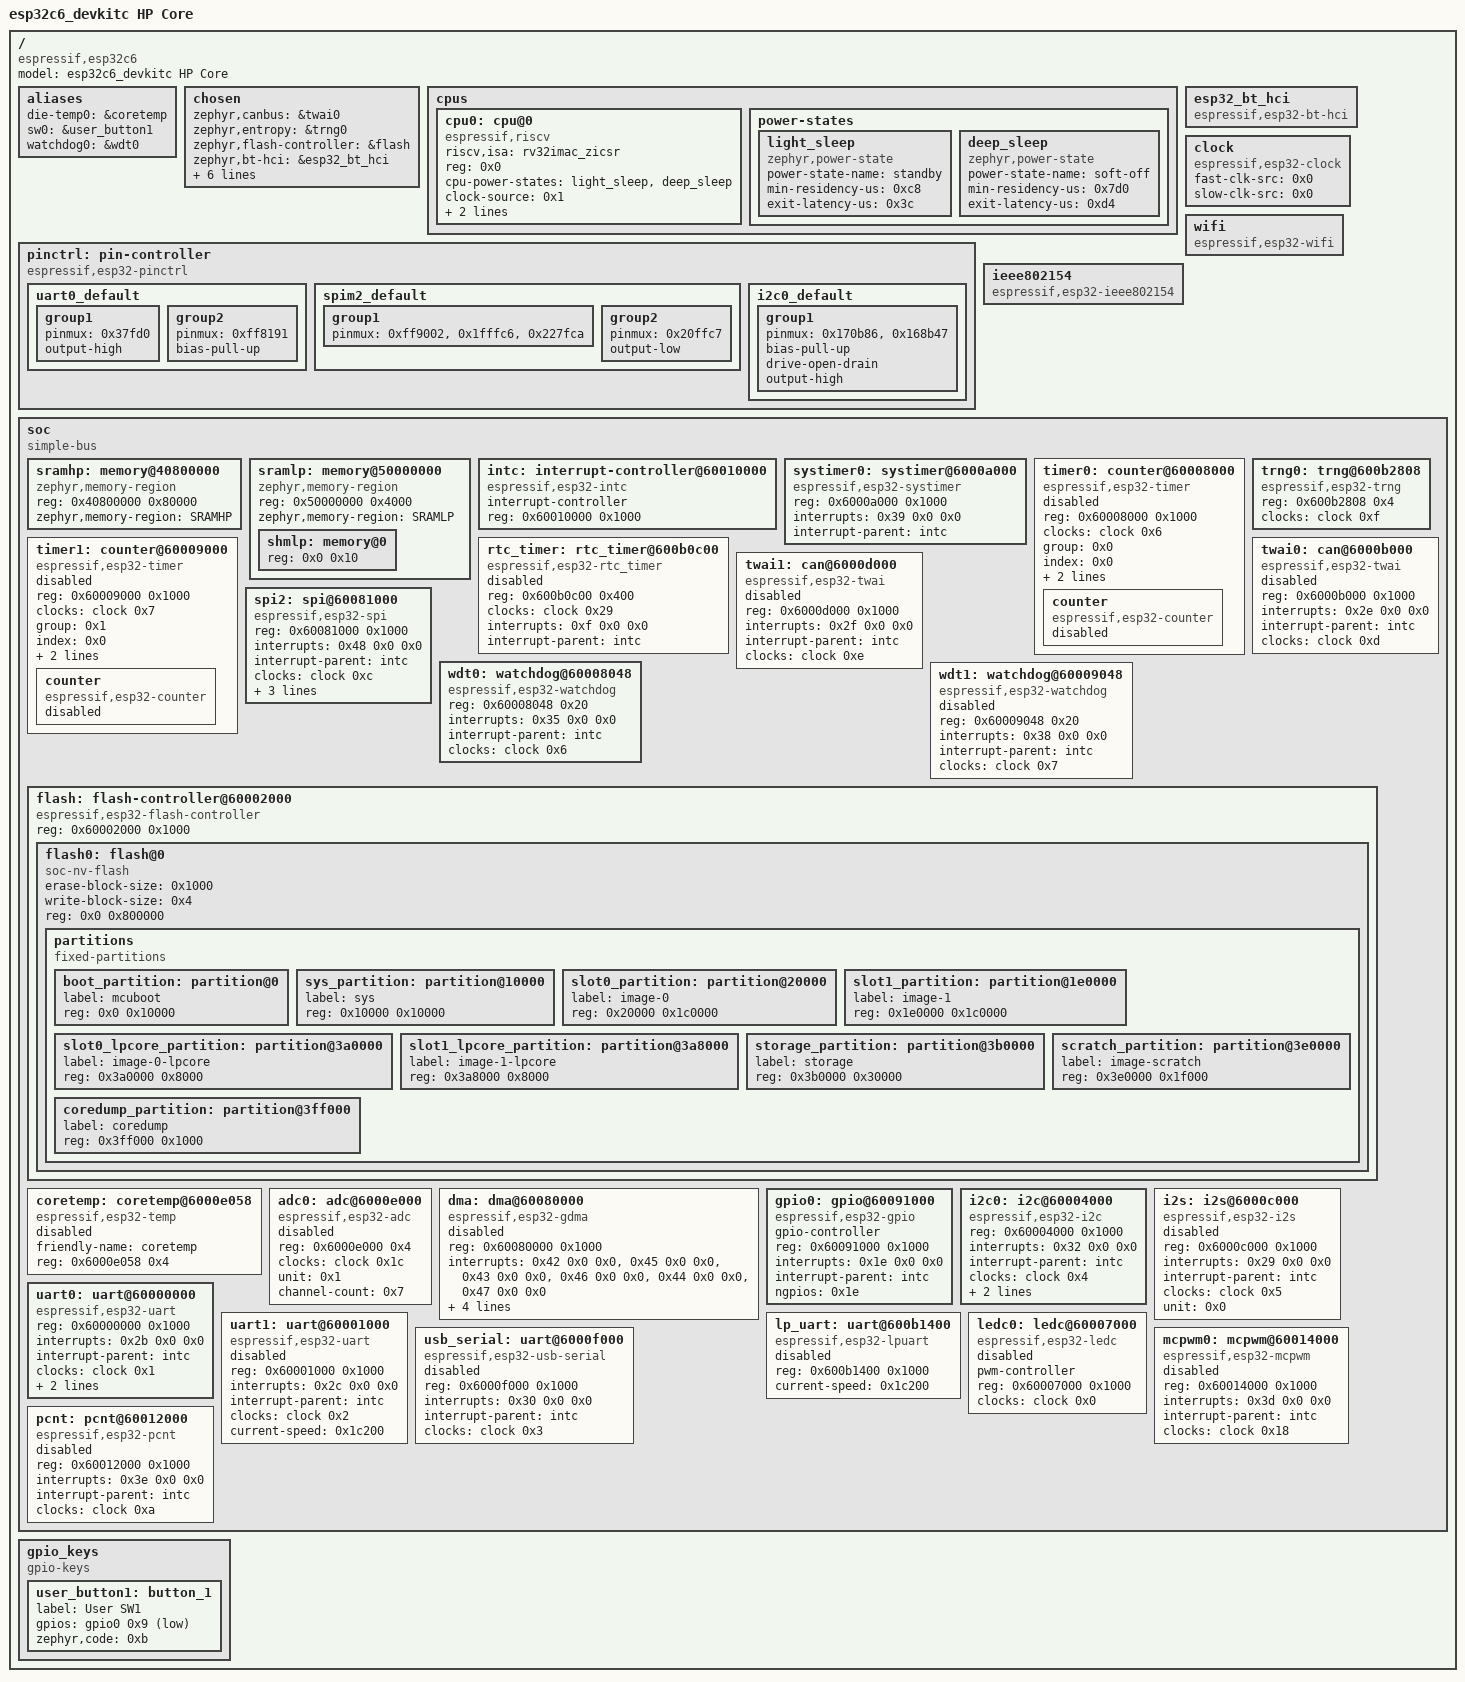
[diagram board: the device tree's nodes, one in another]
/dts-v1/;

/* node '/' defined in zephyr/dts/riscv/espressif/esp32c6/esp32c6_common.dtsi:15 */
/ {
	#address-cells = < 0x1 >;          /* in zephyr/dts/riscv/espressif/esp32c6/esp32c6_common.dtsi:16 */
	#size-cells = < 0x1 >;             /* in zephyr/dts/riscv/espressif/esp32c6/esp32c6_common.dtsi:17 */
	model = "esp32c6_devkitc HP Core"; /* in zephyr/boards/espressif/esp32c6_devkitc/esp32c6_devkitc_hpcore.dts:15 */
	compatible = "espressif,esp32c6";  /* in zephyr/boards/espressif/esp32c6_devkitc/esp32c6_devkitc_hpcore.dts:16 */

	/* node '/aliases' defined in zephyr/dts/riscv/espressif/esp32c6/esp32c6_common.dtsi:19 */
	aliases {
		die-temp0 = &coretemp; /* in zephyr/dts/riscv/espressif/esp32c6/esp32c6_common.dtsi:20 */
		sw0 = &user_button1;   /* in zephyr/boards/espressif/esp32c6_devkitc/esp32c6_devkitc_hpcore.dts:28 */
		watchdog0 = &wdt0;     /* in zephyr/boards/espressif/esp32c6_devkitc/esp32c6_devkitc_hpcore.dts:29 */
	};

	/* node '/chosen' defined in zephyr/dts/riscv/espressif/esp32c6/esp32c6_common.dtsi:23 */
	chosen {
		zephyr,canbus = &twai0;                   /* in zephyr/dts/riscv/espressif/esp32c6/esp32c6_common.dtsi:24 */
		zephyr,entropy = &trng0;                  /* in zephyr/dts/riscv/espressif/esp32c6/esp32c6_common.dtsi:25 */
		zephyr,flash-controller = &flash;         /* in zephyr/dts/riscv/espressif/esp32c6/esp32c6_common.dtsi:26 */
		zephyr,bt-hci = &esp32_bt_hci;            /* in zephyr/dts/riscv/espressif/esp32c6/esp32c6_common.dtsi:27 */
		zephyr,sram = &sramhp;                    /* in zephyr/boards/espressif/esp32c6_devkitc/esp32c6_devkitc_hpcore.dts:19 */
		zephyr,console = &uart0;                  /* in zephyr/boards/espressif/esp32c6_devkitc/esp32c6_devkitc_hpcore.dts:20 */
		zephyr,shell-uart = &uart0;               /* in zephyr/boards/espressif/esp32c6_devkitc/esp32c6_devkitc_hpcore.dts:21 */
		zephyr,flash = &flash0;                   /* in zephyr/boards/espressif/esp32c6_devkitc/esp32c6_devkitc_hpcore.dts:22 */
		zephyr,code-partition = &slot0_partition; /* in zephyr/boards/espressif/esp32c6_devkitc/esp32c6_devkitc_hpcore.dts:23 */
		zephyr,ieee802154 = &ieee802154;          /* in zephyr/boards/espressif/esp32c6_devkitc/esp32c6_devkitc_hpcore.dts:24 */
	};

	/* node '/cpus' defined in zephyr/dts/riscv/espressif/esp32c6/esp32c6_common.dtsi:30 */
	cpus {
		#address-cells = < 0x1 >; /* in zephyr/dts/riscv/espressif/esp32c6/esp32c6_common.dtsi:31 */
		#size-cells = < 0x0 >;    /* in zephyr/dts/riscv/espressif/esp32c6/esp32c6_common.dtsi:32 */

		/* node '/cpus/cpu@0' defined in zephyr/dts/riscv/espressif/esp32c6/esp32c6_common.dtsi:34 */
		cpu0: cpu@0 {
			device_type = "cpu";                             /* in zephyr/dts/riscv/espressif/esp32c6/esp32c6_common.dtsi:35 */
			compatible = "espressif,riscv";                  /* in zephyr/dts/riscv/espressif/esp32c6/esp32c6_common.dtsi:36 */
			riscv,isa = "rv32imac_zicsr";                    /* in zephyr/dts/riscv/espressif/esp32c6/esp32c6_common.dtsi:37 */
			reg = < 0x0 >;                                   /* in zephyr/dts/riscv/espressif/esp32c6/esp32c6_common.dtsi:38 */
			cpu-power-states = < &light_sleep &deep_sleep >; /* in zephyr/dts/riscv/espressif/esp32c6/esp32c6_common.dtsi:39 */
			clock-source = < 0x1 >;                          /* in zephyr/dts/riscv/espressif/esp32c6/esp32c6_common.dtsi:40 */
			clock-frequency = < 0x9896800 >;                 /* in zephyr/dts/riscv/espressif/esp32c6/esp32c6_common.dtsi:41 */
			xtal-freq = < 0x2625a00 >;                       /* in zephyr/dts/riscv/espressif/esp32c6/esp32c6_common.dtsi:42 */
		};

		/* node '/cpus/power-states' defined in zephyr/dts/riscv/espressif/esp32c6/esp32c6_common.dtsi:45 */
		power-states {

			/* node '/cpus/power-states/light_sleep' defined in zephyr/dts/riscv/espressif/esp32c6/esp32c6_common.dtsi:46 */
			light_sleep: light_sleep {
				compatible = "zephyr,power-state"; /* in zephyr/dts/riscv/espressif/esp32c6/esp32c6_common.dtsi:47 */
				power-state-name = "standby";      /* in zephyr/dts/riscv/espressif/esp32c6/esp32c6_common.dtsi:48 */
				min-residency-us = < 0xc8 >;       /* in zephyr/dts/riscv/espressif/esp32c6/esp32c6_common.dtsi:49 */
				exit-latency-us = < 0x3c >;        /* in zephyr/dts/riscv/espressif/esp32c6/esp32c6_common.dtsi:50 */
				phandle = < 0x1 >;                 /* in zephyr/dts/riscv/espressif/esp32c6/esp32c6_common.dtsi:39 */
			};

			/* node '/cpus/power-states/deep_sleep' defined in zephyr/dts/riscv/espressif/esp32c6/esp32c6_common.dtsi:53 */
			deep_sleep: deep_sleep {
				compatible = "zephyr,power-state"; /* in zephyr/dts/riscv/espressif/esp32c6/esp32c6_common.dtsi:54 */
				power-state-name = "soft-off";     /* in zephyr/dts/riscv/espressif/esp32c6/esp32c6_common.dtsi:55 */
				min-residency-us = < 0x7d0 >;      /* in zephyr/dts/riscv/espressif/esp32c6/esp32c6_common.dtsi:56 */
				exit-latency-us = < 0xd4 >;        /* in zephyr/dts/riscv/espressif/esp32c6/esp32c6_common.dtsi:57 */
				phandle = < 0x2 >;                 /* in zephyr/dts/riscv/espressif/esp32c6/esp32c6_common.dtsi:39 */
			};
		};
	};

	/* node '/pin-controller' defined in zephyr/dts/riscv/espressif/esp32c6/esp32c6_common.dtsi:62 */
	pinctrl: pin-controller {
		compatible = "espressif,esp32-pinctrl"; /* in zephyr/dts/riscv/espressif/esp32c6/esp32c6_common.dtsi:63 */
		status = "okay";                        /* in zephyr/dts/riscv/espressif/esp32c6/esp32c6_common.dtsi:64 */

		/* node '/pin-controller/uart0_default' defined in zephyr/boards/espressif/esp32c6_devkitc/esp32c6_devkitc_hpcore-pinctrl.dtsi:13 */
		uart0_default: uart0_default {
			phandle = < 0x7 >; /* in zephyr/boards/espressif/esp32c6_devkitc/esp32c6_devkitc_hpcore.dts:45 */

			/* node '/pin-controller/uart0_default/group1' defined in zephyr/boards/espressif/esp32c6_devkitc/esp32c6_devkitc_hpcore-pinctrl.dtsi:14 */
			group1 {
				pinmux = < 0x37fd0 >; /* in zephyr/boards/espressif/esp32c6_devkitc/esp32c6_devkitc_hpcore-pinctrl.dtsi:15 */
				output-high;          /* in zephyr/boards/espressif/esp32c6_devkitc/esp32c6_devkitc_hpcore-pinctrl.dtsi:16 */
			};

			/* node '/pin-controller/uart0_default/group2' defined in zephyr/boards/espressif/esp32c6_devkitc/esp32c6_devkitc_hpcore-pinctrl.dtsi:18 */
			group2 {
				pinmux = < 0xff8191 >; /* in zephyr/boards/espressif/esp32c6_devkitc/esp32c6_devkitc_hpcore-pinctrl.dtsi:19 */
				bias-pull-up;          /* in zephyr/boards/espressif/esp32c6_devkitc/esp32c6_devkitc_hpcore-pinctrl.dtsi:20 */
			};
		};

		/* node '/pin-controller/spim2_default' defined in zephyr/boards/espressif/esp32c6_devkitc/esp32c6_devkitc_hpcore-pinctrl.dtsi:24 */
		spim2_default: spim2_default {
			phandle = < 0x5 >; /* in zephyr/boards/espressif/esp32c6_devkitc/esp32c6_devkitc_hpcore.dts:64 */

			/* node '/pin-controller/spim2_default/group1' defined in zephyr/boards/espressif/esp32c6_devkitc/esp32c6_devkitc_hpcore-pinctrl.dtsi:25 */
			group1 {
				pinmux = < 0xff9002 >,
				         < 0x1fffc6 >,
				         < 0x227fca >; /* in zephyr/boards/espressif/esp32c6_devkitc/esp32c6_devkitc_hpcore-pinctrl.dtsi:26 */
			};

			/* node '/pin-controller/spim2_default/group2' defined in zephyr/boards/espressif/esp32c6_devkitc/esp32c6_devkitc_hpcore-pinctrl.dtsi:30 */
			group2 {
				pinmux = < 0x20ffc7 >; /* in zephyr/boards/espressif/esp32c6_devkitc/esp32c6_devkitc_hpcore-pinctrl.dtsi:31 */
				output-low;            /* in zephyr/boards/espressif/esp32c6_devkitc/esp32c6_devkitc_hpcore-pinctrl.dtsi:32 */
			};
		};

		/* node '/pin-controller/i2c0_default' defined in zephyr/boards/espressif/esp32c6_devkitc/esp32c6_devkitc_hpcore-pinctrl.dtsi:36 */
		i2c0_default: i2c0_default {
			phandle = < 0x6 >; /* in zephyr/boards/espressif/esp32c6_devkitc/esp32c6_devkitc_hpcore.dts:56 */

			/* node '/pin-controller/i2c0_default/group1' defined in zephyr/boards/espressif/esp32c6_devkitc/esp32c6_devkitc_hpcore-pinctrl.dtsi:37 */
			group1 {
				pinmux = < 0x170b86 >,
				         < 0x168b47 >; /* in zephyr/boards/espressif/esp32c6_devkitc/esp32c6_devkitc_hpcore-pinctrl.dtsi:38 */
				bias-pull-up;          /* in zephyr/boards/espressif/esp32c6_devkitc/esp32c6_devkitc_hpcore-pinctrl.dtsi:40 */
				drive-open-drain;      /* in zephyr/boards/espressif/esp32c6_devkitc/esp32c6_devkitc_hpcore-pinctrl.dtsi:41 */
				output-high;           /* in zephyr/boards/espressif/esp32c6_devkitc/esp32c6_devkitc_hpcore-pinctrl.dtsi:42 */
			};
		};
	};

	/* node '/esp32_bt_hci' defined in zephyr/dts/riscv/espressif/esp32c6/esp32c6_common.dtsi:67 */
	esp32_bt_hci: esp32_bt_hci {
		compatible = "espressif,esp32-bt-hci"; /* in zephyr/dts/riscv/espressif/esp32c6/esp32c6_common.dtsi:68 */
		status = "okay";                       /* in zephyr/boards/espressif/esp32c6_devkitc/esp32c6_devkitc_hpcore.dts:85 */
	};

	/* node '/clock' defined in zephyr/dts/riscv/espressif/esp32c6/esp32c6_common.dtsi:72 */
	clock: clock {
		compatible = "espressif,esp32-clock"; /* in zephyr/dts/riscv/espressif/esp32c6/esp32c6_common.dtsi:73 */
		fast-clk-src = < 0x0 >;               /* in zephyr/dts/riscv/espressif/esp32c6/esp32c6_common.dtsi:74 */
		slow-clk-src = < 0x0 >;               /* in zephyr/dts/riscv/espressif/esp32c6/esp32c6_common.dtsi:75 */
		#clock-cells = < 0x1 >;               /* in zephyr/dts/riscv/espressif/esp32c6/esp32c6_common.dtsi:76 */
		status = "okay";                      /* in zephyr/dts/riscv/espressif/esp32c6/esp32c6_common.dtsi:77 */
		phandle = < 0x4 >;                    /* in zephyr/dts/riscv/espressif/esp32c6/esp32c6_common.dtsi:134 */
	};

	/* node '/wifi' defined in zephyr/dts/riscv/espressif/esp32c6/esp32c6_common.dtsi:80 */
	wifi: wifi {
		compatible = "espressif,esp32-wifi"; /* in zephyr/dts/riscv/espressif/esp32c6/esp32c6_common.dtsi:81 */
		status = "okay";                     /* in zephyr/boards/espressif/esp32c6_devkitc/esp32c6_devkitc_hpcore.dts:77 */
	};

	/* node '/ieee802154' defined in zephyr/dts/riscv/espressif/esp32c6/esp32c6_common.dtsi:85 */
	ieee802154: ieee802154 {
		compatible = "espressif,esp32-ieee802154"; /* in zephyr/dts/riscv/espressif/esp32c6/esp32c6_common.dtsi:86 */
		status = "okay";                           /* in zephyr/boards/espressif/esp32c6_devkitc/esp32c6_devkitc_hpcore.dts:81 */
	};

	/* node '/soc' defined in zephyr/dts/riscv/espressif/esp32c6/esp32c6_common.dtsi:90 */
	soc {
		#address-cells = < 0x1 >;  /* in zephyr/dts/riscv/espressif/esp32c6/esp32c6_common.dtsi:91 */
		#size-cells = < 0x1 >;     /* in zephyr/dts/riscv/espressif/esp32c6/esp32c6_common.dtsi:92 */
		compatible = "simple-bus"; /* in zephyr/dts/riscv/espressif/esp32c6/esp32c6_common.dtsi:93 */
		ranges;                    /* in zephyr/dts/riscv/espressif/esp32c6/esp32c6_common.dtsi:94 */

		/* node '/soc/memory@40800000' defined in zephyr/dts/riscv/espressif/esp32c6/esp32c6_common.dtsi:96 */
		sramhp: memory@40800000 {
			compatible = "zephyr,memory-region",
			             "mmio-sram";            /* in zephyr/dts/riscv/espressif/esp32c6/esp32c6_common.dtsi:97 */
			reg = < 0x40800000 0x80000 >;        /* in zephyr/dts/riscv/espressif/esp32c6/esp32c6_common.dtsi:98 */
			zephyr,memory-region = "SRAMHP";     /* in zephyr/dts/riscv/espressif/esp32c6/esp32c6_common.dtsi:99 */
		};

		/* node '/soc/memory@50000000' defined in zephyr/dts/riscv/espressif/esp32c6/esp32c6_common.dtsi:102 */
		sramlp: memory@50000000 {
			#address-cells = < 0x1 >;            /* in zephyr/dts/riscv/espressif/esp32c6/esp32c6_common.dtsi:103 */
			#size-cells = < 0x1 >;               /* in zephyr/dts/riscv/espressif/esp32c6/esp32c6_common.dtsi:104 */
			compatible = "zephyr,memory-region",
			             "mmio-sram";            /* in zephyr/dts/riscv/espressif/esp32c6/esp32c6_common.dtsi:105 */
			reg = < 0x50000000 0x4000 >;         /* in zephyr/dts/riscv/espressif/esp32c6/esp32c6_common.dtsi:106 */
			zephyr,memory-region = "SRAMLP ";    /* in zephyr/dts/riscv/espressif/esp32c6/esp32c6_common.dtsi:107 */

			/* node '/soc/memory@50000000/memory@0' defined in zephyr/dts/riscv/espressif/esp32c6/esp32c6_common.dtsi:109 */
			shmlp: memory@0 {
				reg = < 0x0 0x10 >; /* in zephyr/dts/riscv/espressif/esp32c6/esp32c6_common.dtsi:110 */
			};
		};

		/* node '/soc/interrupt-controller@60010000' defined in zephyr/dts/riscv/espressif/esp32c6/esp32c6_common.dtsi:114 */
		intc: interrupt-controller@60010000 {
			compatible = "espressif,esp32-intc"; /* in zephyr/dts/riscv/espressif/esp32c6/esp32c6_common.dtsi:115 */
			#address-cells = < 0x0 >;            /* in zephyr/dts/riscv/espressif/esp32c6/esp32c6_common.dtsi:116 */
			#interrupt-cells = < 0x3 >;          /* in zephyr/dts/riscv/espressif/esp32c6/esp32c6_common.dtsi:117 */
			interrupt-controller;                /* in zephyr/dts/riscv/espressif/esp32c6/esp32c6_common.dtsi:118 */
			reg = < 0x60010000 0x1000 >;         /* in zephyr/dts/riscv/espressif/esp32c6/esp32c6_common.dtsi:119 */
			status = "okay";                     /* in zephyr/dts/riscv/espressif/esp32c6/esp32c6_common.dtsi:120 */
			phandle = < 0x3 >;                   /* in zephyr/dts/riscv/espressif/esp32c6/esp32c6_common.dtsi:127 */
		};

		/* node '/soc/systimer@6000a000' defined in zephyr/dts/riscv/espressif/esp32c6/esp32c6_common.dtsi:123 */
		systimer0: systimer@6000a000 {
			compatible = "espressif,esp32-systimer"; /* in zephyr/dts/riscv/espressif/esp32c6/esp32c6_common.dtsi:124 */
			reg = < 0x6000a000 0x1000 >;             /* in zephyr/dts/riscv/espressif/esp32c6/esp32c6_common.dtsi:125 */
			interrupts = < 0x39 0x0 0x0 >;           /* in zephyr/dts/riscv/espressif/esp32c6/esp32c6_common.dtsi:126 */
			interrupt-parent = < &intc >;            /* in zephyr/dts/riscv/espressif/esp32c6/esp32c6_common.dtsi:127 */
			status = "okay";                         /* in zephyr/dts/riscv/espressif/esp32c6/esp32c6_common.dtsi:128 */
		};

		/* node '/soc/counter@60008000' defined in zephyr/dts/riscv/espressif/esp32c6/esp32c6_common.dtsi:131 */
		timer0: counter@60008000 {
			compatible = "espressif,esp32-timer"; /* in zephyr/dts/riscv/espressif/esp32c6/esp32c6_common.dtsi:132 */
			reg = < 0x60008000 0x1000 >;          /* in zephyr/dts/riscv/espressif/esp32c6/esp32c6_common.dtsi:133 */
			clocks = < &clock 0x6 >;              /* in zephyr/dts/riscv/espressif/esp32c6/esp32c6_common.dtsi:134 */
			group = < 0x0 >;                      /* in zephyr/dts/riscv/espressif/esp32c6/esp32c6_common.dtsi:135 */
			index = < 0x0 >;                      /* in zephyr/dts/riscv/espressif/esp32c6/esp32c6_common.dtsi:136 */
			interrupts = < 0x33 0x0 0x0 >;        /* in zephyr/dts/riscv/espressif/esp32c6/esp32c6_common.dtsi:137 */
			interrupt-parent = < &intc >;         /* in zephyr/dts/riscv/espressif/esp32c6/esp32c6_common.dtsi:138 */
			status = "disabled";                  /* in zephyr/dts/riscv/espressif/esp32c6/esp32c6_common.dtsi:139 */

			/* node '/soc/counter@60008000/counter' defined in zephyr/dts/riscv/espressif/esp32c6/esp32c6_common.dtsi:141 */
			counter {
				compatible = "espressif,esp32-counter"; /* in zephyr/dts/riscv/espressif/esp32c6/esp32c6_common.dtsi:142 */
				status = "disabled";                    /* in zephyr/dts/riscv/espressif/esp32c6/esp32c6_common.dtsi:143 */
			};
		};

		/* node '/soc/counter@60009000' defined in zephyr/dts/riscv/espressif/esp32c6/esp32c6_common.dtsi:147 */
		timer1: counter@60009000 {
			compatible = "espressif,esp32-timer"; /* in zephyr/dts/riscv/espressif/esp32c6/esp32c6_common.dtsi:148 */
			reg = < 0x60009000 0x1000 >;          /* in zephyr/dts/riscv/espressif/esp32c6/esp32c6_common.dtsi:149 */
			clocks = < &clock 0x7 >;              /* in zephyr/dts/riscv/espressif/esp32c6/esp32c6_common.dtsi:150 */
			group = < 0x1 >;                      /* in zephyr/dts/riscv/espressif/esp32c6/esp32c6_common.dtsi:151 */
			index = < 0x0 >;                      /* in zephyr/dts/riscv/espressif/esp32c6/esp32c6_common.dtsi:152 */
			interrupts = < 0x36 0x0 0x0 >;        /* in zephyr/dts/riscv/espressif/esp32c6/esp32c6_common.dtsi:153 */
			interrupt-parent = < &intc >;         /* in zephyr/dts/riscv/espressif/esp32c6/esp32c6_common.dtsi:154 */
			status = "disabled";                  /* in zephyr/dts/riscv/espressif/esp32c6/esp32c6_common.dtsi:155 */

			/* node '/soc/counter@60009000/counter' defined in zephyr/dts/riscv/espressif/esp32c6/esp32c6_common.dtsi:157 */
			counter {
				compatible = "espressif,esp32-counter"; /* in zephyr/dts/riscv/espressif/esp32c6/esp32c6_common.dtsi:158 */
				status = "disabled";                    /* in zephyr/dts/riscv/espressif/esp32c6/esp32c6_common.dtsi:159 */
			};
		};

		/* node '/soc/rtc_timer@600b0c00' defined in zephyr/dts/riscv/espressif/esp32c6/esp32c6_common.dtsi:163 */
		rtc_timer: rtc_timer@600b0c00 {
			compatible = "espressif,esp32-rtc_timer"; /* in zephyr/dts/riscv/espressif/esp32c6/esp32c6_common.dtsi:164 */
			reg = < 0x600b0c00 0x400 >;               /* in zephyr/dts/riscv/espressif/esp32c6/esp32c6_common.dtsi:165 */
			clocks = < &clock 0x29 >;                 /* in zephyr/dts/riscv/espressif/esp32c6/esp32c6_common.dtsi:166 */
			interrupts = < 0xf 0x0 0x0 >;             /* in zephyr/dts/riscv/espressif/esp32c6/esp32c6_common.dtsi:167 */
			interrupt-parent = < &intc >;             /* in zephyr/dts/riscv/espressif/esp32c6/esp32c6_common.dtsi:168 */
			status = "disabled";                      /* in zephyr/dts/riscv/espressif/esp32c6/esp32c6_common.dtsi:169 */
		};

		/* node '/soc/trng@600b2808' defined in zephyr/dts/riscv/espressif/esp32c6/esp32c6_common.dtsi:172 */
		trng0: trng@600b2808 {
			compatible = "espressif,esp32-trng"; /* in zephyr/dts/riscv/espressif/esp32c6/esp32c6_common.dtsi:173 */
			reg = < 0x600b2808 0x4 >;            /* in zephyr/dts/riscv/espressif/esp32c6/esp32c6_common.dtsi:174 */
			clocks = < &clock 0xf >;             /* in zephyr/dts/riscv/espressif/esp32c6/esp32c6_common.dtsi:175 */
			status = "okay";                     /* in zephyr/boards/espressif/esp32c6_devkitc/esp32c6_devkitc_hpcore.dts:50 */
		};

		/* node '/soc/can@6000b000' defined in zephyr/dts/riscv/espressif/esp32c6/esp32c6_common.dtsi:179 */
		twai0: can@6000b000 {
			compatible = "espressif,esp32-twai"; /* in zephyr/dts/riscv/espressif/esp32c6/esp32c6_common.dtsi:180 */
			reg = < 0x6000b000 0x1000 >;         /* in zephyr/dts/riscv/espressif/esp32c6/esp32c6_common.dtsi:181 */
			interrupts = < 0x2e 0x0 0x0 >;       /* in zephyr/dts/riscv/espressif/esp32c6/esp32c6_common.dtsi:182 */
			interrupt-parent = < &intc >;        /* in zephyr/dts/riscv/espressif/esp32c6/esp32c6_common.dtsi:183 */
			clocks = < &clock 0xd >;             /* in zephyr/dts/riscv/espressif/esp32c6/esp32c6_common.dtsi:184 */
			status = "disabled";                 /* in zephyr/dts/riscv/espressif/esp32c6/esp32c6_common.dtsi:185 */
		};

		/* node '/soc/can@6000d000' defined in zephyr/dts/riscv/espressif/esp32c6/esp32c6_common.dtsi:188 */
		twai1: can@6000d000 {
			compatible = "espressif,esp32-twai"; /* in zephyr/dts/riscv/espressif/esp32c6/esp32c6_common.dtsi:189 */
			reg = < 0x6000d000 0x1000 >;         /* in zephyr/dts/riscv/espressif/esp32c6/esp32c6_common.dtsi:190 */
			interrupts = < 0x2f 0x0 0x0 >;       /* in zephyr/dts/riscv/espressif/esp32c6/esp32c6_common.dtsi:191 */
			interrupt-parent = < &intc >;        /* in zephyr/dts/riscv/espressif/esp32c6/esp32c6_common.dtsi:192 */
			clocks = < &clock 0xe >;             /* in zephyr/dts/riscv/espressif/esp32c6/esp32c6_common.dtsi:193 */
			status = "disabled";                 /* in zephyr/dts/riscv/espressif/esp32c6/esp32c6_common.dtsi:194 */
		};

		/* node '/soc/spi@60081000' defined in zephyr/dts/riscv/espressif/esp32c6/esp32c6_common.dtsi:197 */
		spi2: spi@60081000 {
			compatible = "espressif,esp32-spi"; /* in zephyr/dts/riscv/espressif/esp32c6/esp32c6_common.dtsi:198 */
			reg = < 0x60081000 0x1000 >;        /* in zephyr/dts/riscv/espressif/esp32c6/esp32c6_common.dtsi:199 */
			interrupts = < 0x48 0x0 0x0 >;      /* in zephyr/dts/riscv/espressif/esp32c6/esp32c6_common.dtsi:200 */
			interrupt-parent = < &intc >;       /* in zephyr/dts/riscv/espressif/esp32c6/esp32c6_common.dtsi:201 */
			clocks = < &clock 0xc >;            /* in zephyr/dts/riscv/espressif/esp32c6/esp32c6_common.dtsi:202 */
			dma-clk = < 0x17 >;                 /* in zephyr/dts/riscv/espressif/esp32c6/esp32c6_common.dtsi:203 */
			dma-host = < 0x0 >;                 /* in zephyr/dts/riscv/espressif/esp32c6/esp32c6_common.dtsi:204 */
			#address-cells = < 0x1 >;           /* in zephyr/boards/espressif/esp32c6_devkitc/esp32c6_devkitc_hpcore.dts:61 */
			#size-cells = < 0x0 >;              /* in zephyr/boards/espressif/esp32c6_devkitc/esp32c6_devkitc_hpcore.dts:62 */
			status = "okay";                    /* in zephyr/boards/espressif/esp32c6_devkitc/esp32c6_devkitc_hpcore.dts:63 */
			pinctrl-0 = < &spim2_default >;     /* in zephyr/boards/espressif/esp32c6_devkitc/esp32c6_devkitc_hpcore.dts:64 */
			pinctrl-names = "default";          /* in zephyr/boards/espressif/esp32c6_devkitc/esp32c6_devkitc_hpcore.dts:65 */
		};

		/* node '/soc/watchdog@60008048' defined in zephyr/dts/riscv/espressif/esp32c6/esp32c6_common.dtsi:208 */
		wdt0: watchdog@60008048 {
			compatible = "espressif,esp32-watchdog"; /* in zephyr/dts/riscv/espressif/esp32c6/esp32c6_common.dtsi:209 */
			reg = < 0x60008048 0x20 >;               /* in zephyr/dts/riscv/espressif/esp32c6/esp32c6_common.dtsi:210 */
			interrupts = < 0x35 0x0 0x0 >;           /* in zephyr/dts/riscv/espressif/esp32c6/esp32c6_common.dtsi:211 */
			interrupt-parent = < &intc >;            /* in zephyr/dts/riscv/espressif/esp32c6/esp32c6_common.dtsi:212 */
			clocks = < &clock 0x6 >;                 /* in zephyr/dts/riscv/espressif/esp32c6/esp32c6_common.dtsi:213 */
			status = "okay";                         /* in zephyr/boards/espressif/esp32c6_devkitc/esp32c6_devkitc_hpcore.dts:73 */
		};

		/* node '/soc/watchdog@60009048' defined in zephyr/dts/riscv/espressif/esp32c6/esp32c6_common.dtsi:217 */
		wdt1: watchdog@60009048 {
			compatible = "espressif,esp32-watchdog"; /* in zephyr/dts/riscv/espressif/esp32c6/esp32c6_common.dtsi:218 */
			reg = < 0x60009048 0x20 >;               /* in zephyr/dts/riscv/espressif/esp32c6/esp32c6_common.dtsi:219 */
			interrupts = < 0x38 0x0 0x0 >;           /* in zephyr/dts/riscv/espressif/esp32c6/esp32c6_common.dtsi:220 */
			interrupt-parent = < &intc >;            /* in zephyr/dts/riscv/espressif/esp32c6/esp32c6_common.dtsi:221 */
			clocks = < &clock 0x7 >;                 /* in zephyr/dts/riscv/espressif/esp32c6/esp32c6_common.dtsi:222 */
			status = "disabled";                     /* in zephyr/dts/riscv/espressif/esp32c6/esp32c6_common.dtsi:223 */
		};

		/* node '/soc/flash-controller@60002000' defined in zephyr/dts/riscv/espressif/esp32c6/esp32c6_common.dtsi:226 */
		flash: flash-controller@60002000 {
			compatible = "espressif,esp32-flash-controller"; /* in zephyr/dts/riscv/espressif/esp32c6/esp32c6_common.dtsi:227 */
			reg = < 0x60002000 0x1000 >;                     /* in zephyr/dts/riscv/espressif/esp32c6/esp32c6_common.dtsi:228 */
			#address-cells = < 0x1 >;                        /* in zephyr/dts/riscv/espressif/esp32c6/esp32c6_common.dtsi:230 */
			#size-cells = < 0x1 >;                           /* in zephyr/dts/riscv/espressif/esp32c6/esp32c6_common.dtsi:231 */

			/* node '/soc/flash-controller@60002000/flash@0' defined in zephyr/dts/riscv/espressif/esp32c6/esp32c6_common.dtsi:233 */
			flash0: flash@0 {
				compatible = "soc-nv-flash";   /* in zephyr/dts/riscv/espressif/esp32c6/esp32c6_common.dtsi:234 */
				erase-block-size = < 0x1000 >; /* in zephyr/dts/riscv/espressif/esp32c6/esp32c6_common.dtsi:235 */
				write-block-size = < 0x4 >;    /* in zephyr/dts/riscv/espressif/esp32c6/esp32c6_common.dtsi:236 */
				reg = < 0x0 0x800000 >;        /* in zephyr/dts/riscv/espressif/esp32c6/esp32c6_wroom_n8.dtsi:11 */

				/* node '/soc/flash-controller@60002000/flash@0/partitions' defined in zephyr/dts/vendor/espressif/partitions_0x0_default_4M.dtsi:8 */
				partitions {
					compatible = "fixed-partitions"; /* in zephyr/dts/vendor/espressif/partitions_0x0_default_4M.dtsi:9 */
					#address-cells = < 0x1 >;        /* in zephyr/dts/vendor/espressif/partitions_0x0_default_4M.dtsi:10 */
					#size-cells = < 0x1 >;           /* in zephyr/dts/vendor/espressif/partitions_0x0_default_4M.dtsi:11 */

					/* node '/soc/flash-controller@60002000/flash@0/partitions/partition@0' defined in zephyr/dts/vendor/espressif/partitions_0x0_default_4M.dtsi:13 */
					boot_partition: partition@0 {
						label = "mcuboot";     /* in zephyr/dts/vendor/espressif/partitions_0x0_default_4M.dtsi:14 */
						reg = < 0x0 0x10000 >; /* in zephyr/dts/vendor/espressif/partitions_0x0_default_4M.dtsi:15 */
					};

					/* node '/soc/flash-controller@60002000/flash@0/partitions/partition@10000' defined in zephyr/dts/vendor/espressif/partitions_0x0_default_4M.dtsi:18 */
					sys_partition: partition@10000 {
						label = "sys";             /* in zephyr/dts/vendor/espressif/partitions_0x0_default_4M.dtsi:19 */
						reg = < 0x10000 0x10000 >; /* in zephyr/dts/vendor/espressif/partitions_0x0_default_4M.dtsi:20 */
					};

					/* node '/soc/flash-controller@60002000/flash@0/partitions/partition@20000' defined in zephyr/dts/vendor/espressif/partitions_0x0_default_4M.dtsi:23 */
					slot0_partition: partition@20000 {
						label = "image-0";          /* in zephyr/dts/vendor/espressif/partitions_0x0_default_4M.dtsi:24 */
						reg = < 0x20000 0x1c0000 >; /* in zephyr/dts/vendor/espressif/partitions_0x0_default_4M.dtsi:25 */
					};

					/* node '/soc/flash-controller@60002000/flash@0/partitions/partition@1e0000' defined in zephyr/dts/vendor/espressif/partitions_0x0_default_4M.dtsi:28 */
					slot1_partition: partition@1e0000 {
						label = "image-1";           /* in zephyr/dts/vendor/espressif/partitions_0x0_default_4M.dtsi:29 */
						reg = < 0x1e0000 0x1c0000 >; /* in zephyr/dts/vendor/espressif/partitions_0x0_default_4M.dtsi:30 */
					};

					/* node '/soc/flash-controller@60002000/flash@0/partitions/partition@3a0000' defined in zephyr/dts/vendor/espressif/partitions_0x0_default_4M.dtsi:33 */
					slot0_lpcore_partition: partition@3a0000 {
						label = "image-0-lpcore";  /* in zephyr/dts/vendor/espressif/partitions_0x0_default_4M.dtsi:34 */
						reg = < 0x3a0000 0x8000 >; /* in zephyr/dts/vendor/espressif/partitions_0x0_default_4M.dtsi:35 */
					};

					/* node '/soc/flash-controller@60002000/flash@0/partitions/partition@3a8000' defined in zephyr/dts/vendor/espressif/partitions_0x0_default_4M.dtsi:38 */
					slot1_lpcore_partition: partition@3a8000 {
						label = "image-1-lpcore";  /* in zephyr/dts/vendor/espressif/partitions_0x0_default_4M.dtsi:39 */
						reg = < 0x3a8000 0x8000 >; /* in zephyr/dts/vendor/espressif/partitions_0x0_default_4M.dtsi:40 */
					};

					/* node '/soc/flash-controller@60002000/flash@0/partitions/partition@3b0000' defined in zephyr/dts/vendor/espressif/partitions_0x0_default_4M.dtsi:43 */
					storage_partition: partition@3b0000 {
						label = "storage";          /* in zephyr/dts/vendor/espressif/partitions_0x0_default_4M.dtsi:44 */
						reg = < 0x3b0000 0x30000 >; /* in zephyr/dts/vendor/espressif/partitions_0x0_default_4M.dtsi:45 */
					};

					/* node '/soc/flash-controller@60002000/flash@0/partitions/partition@3e0000' defined in zephyr/dts/vendor/espressif/partitions_0x0_default_4M.dtsi:48 */
					scratch_partition: partition@3e0000 {
						label = "image-scratch";    /* in zephyr/dts/vendor/espressif/partitions_0x0_default_4M.dtsi:49 */
						reg = < 0x3e0000 0x1f000 >; /* in zephyr/dts/vendor/espressif/partitions_0x0_default_4M.dtsi:50 */
					};

					/* node '/soc/flash-controller@60002000/flash@0/partitions/partition@3ff000' defined in zephyr/dts/vendor/espressif/partitions_0x0_default_4M.dtsi:53 */
					coredump_partition: partition@3ff000 {
						label = "coredump";        /* in zephyr/dts/vendor/espressif/partitions_0x0_default_4M.dtsi:54 */
						reg = < 0x3ff000 0x1000 >; /* in zephyr/dts/vendor/espressif/partitions_0x0_default_4M.dtsi:55 */
					};
				};
			};
		};

		/* node '/soc/coretemp@6000e058' defined in zephyr/dts/riscv/espressif/esp32c6/esp32c6_common.dtsi:241 */
		coretemp: coretemp@6000e058 {
			compatible = "espressif,esp32-temp"; /* in zephyr/dts/riscv/espressif/esp32c6/esp32c6_common.dtsi:242 */
			friendly-name = "coretemp";          /* in zephyr/dts/riscv/espressif/esp32c6/esp32c6_common.dtsi:243 */
			reg = < 0x6000e058 0x4 >;            /* in zephyr/dts/riscv/espressif/esp32c6/esp32c6_common.dtsi:244 */
			status = "disabled";                 /* in zephyr/dts/riscv/espressif/esp32c6/esp32c6_common.dtsi:245 */
		};

		/* node '/soc/adc@6000e000' defined in zephyr/dts/riscv/espressif/esp32c6/esp32c6_common.dtsi:248 */
		adc0: adc@6000e000 {
			compatible = "espressif,esp32-adc"; /* in zephyr/dts/riscv/espressif/esp32c6/esp32c6_common.dtsi:249 */
			reg = < 0x6000e000 0x4 >;           /* in zephyr/dts/riscv/espressif/esp32c6/esp32c6_common.dtsi:250 */
			clocks = < &clock 0x1c >;           /* in zephyr/dts/riscv/espressif/esp32c6/esp32c6_common.dtsi:251 */
			unit = < 0x1 >;                     /* in zephyr/dts/riscv/espressif/esp32c6/esp32c6_common.dtsi:252 */
			channel-count = < 0x7 >;            /* in zephyr/dts/riscv/espressif/esp32c6/esp32c6_common.dtsi:253 */
			#io-channel-cells = < 0x1 >;        /* in zephyr/dts/riscv/espressif/esp32c6/esp32c6_common.dtsi:254 */
			status = "disabled";                /* in zephyr/dts/riscv/espressif/esp32c6/esp32c6_common.dtsi:255 */
		};

		/* node '/soc/dma@60080000' defined in zephyr/dts/riscv/espressif/esp32c6/esp32c6_common.dtsi:258 */
		dma: dma@60080000 {
			compatible = "espressif,esp32-gdma"; /* in zephyr/dts/riscv/espressif/esp32c6/esp32c6_common.dtsi:259 */
			reg = < 0x60080000 0x1000 >;         /* in zephyr/dts/riscv/espressif/esp32c6/esp32c6_common.dtsi:260 */
			#dma-cells = < 0x1 >;                /* in zephyr/dts/riscv/espressif/esp32c6/esp32c6_common.dtsi:261 */
			interrupts = < 0x42 0x0 0x0 >,
			             < 0x45 0x0 0x0 >,
			             < 0x43 0x0 0x0 >,
			             < 0x46 0x0 0x0 >,
			             < 0x44 0x0 0x0 >,
			             < 0x47 0x0 0x0 >;       /* in zephyr/dts/riscv/espressif/esp32c6/esp32c6_common.dtsi:262 */
			interrupt-parent = < &intc >;        /* in zephyr/dts/riscv/espressif/esp32c6/esp32c6_common.dtsi:269 */
			clocks = < &clock 0x17 >;            /* in zephyr/dts/riscv/espressif/esp32c6/esp32c6_common.dtsi:270 */
			dma-channels = < 0x6 >;              /* in zephyr/dts/riscv/espressif/esp32c6/esp32c6_common.dtsi:271 */
			dma-buf-addr-alignment = < 0x4 >;    /* in zephyr/dts/riscv/espressif/esp32c6/esp32c6_common.dtsi:272 */
			status = "disabled";                 /* in zephyr/dts/riscv/espressif/esp32c6/esp32c6_common.dtsi:273 */
		};

		/* node '/soc/gpio@60091000' defined in zephyr/dts/riscv/espressif/esp32c6/esp32c6_common.dtsi:276 */
		gpio0: gpio@60091000 {
			compatible = "espressif,esp32-gpio"; /* in zephyr/dts/riscv/espressif/esp32c6/esp32c6_common.dtsi:277 */
			gpio-controller;                     /* in zephyr/dts/riscv/espressif/esp32c6/esp32c6_common.dtsi:278 */
			#gpio-cells = < 0x2 >;               /* in zephyr/dts/riscv/espressif/esp32c6/esp32c6_common.dtsi:279 */
			reg = < 0x60091000 0x1000 >;         /* in zephyr/dts/riscv/espressif/esp32c6/esp32c6_common.dtsi:280 */
			interrupts = < 0x1e 0x0 0x0 >;       /* in zephyr/dts/riscv/espressif/esp32c6/esp32c6_common.dtsi:281 */
			interrupt-parent = < &intc >;        /* in zephyr/dts/riscv/espressif/esp32c6/esp32c6_common.dtsi:282 */
			ngpios = < 0x1e >;                   /* in zephyr/dts/riscv/espressif/esp32c6/esp32c6_common.dtsi:283 */
			status = "okay";                     /* in zephyr/boards/espressif/esp32c6_devkitc/esp32c6_devkitc_hpcore.dts:69 */
			phandle = < 0x8 >;                   /* in zephyr/boards/espressif/esp32c6_devkitc/esp32c6_devkitc_hpcore.dts:36 */
		};

		/* node '/soc/i2c@60004000' defined in zephyr/dts/riscv/espressif/esp32c6/esp32c6_common.dtsi:286 */
		i2c0: i2c@60004000 {
			compatible = "espressif,esp32-i2c"; /* in zephyr/dts/riscv/espressif/esp32c6/esp32c6_common.dtsi:287 */
			#address-cells = < 0x1 >;           /* in zephyr/dts/riscv/espressif/esp32c6/esp32c6_common.dtsi:288 */
			#size-cells = < 0x0 >;              /* in zephyr/dts/riscv/espressif/esp32c6/esp32c6_common.dtsi:289 */
			reg = < 0x60004000 0x1000 >;        /* in zephyr/dts/riscv/espressif/esp32c6/esp32c6_common.dtsi:290 */
			interrupts = < 0x32 0x0 0x0 >;      /* in zephyr/dts/riscv/espressif/esp32c6/esp32c6_common.dtsi:291 */
			interrupt-parent = < &intc >;       /* in zephyr/dts/riscv/espressif/esp32c6/esp32c6_common.dtsi:292 */
			clocks = < &clock 0x4 >;            /* in zephyr/dts/riscv/espressif/esp32c6/esp32c6_common.dtsi:293 */
			status = "okay";                    /* in zephyr/boards/espressif/esp32c6_devkitc/esp32c6_devkitc_hpcore.dts:54 */
			clock-frequency = < 0x61a80 >;      /* in zephyr/boards/espressif/esp32c6_devkitc/esp32c6_devkitc_hpcore.dts:55 */
			pinctrl-0 = < &i2c0_default >;      /* in zephyr/boards/espressif/esp32c6_devkitc/esp32c6_devkitc_hpcore.dts:56 */
			pinctrl-names = "default";          /* in zephyr/boards/espressif/esp32c6_devkitc/esp32c6_devkitc_hpcore.dts:57 */
		};

		/* node '/soc/i2s@6000c000' defined in zephyr/dts/riscv/espressif/esp32c6/esp32c6_common.dtsi:297 */
		i2s: i2s@6000c000 {
			compatible = "espressif,esp32-i2s"; /* in zephyr/dts/riscv/espressif/esp32c6/esp32c6_common.dtsi:298 */
			#address-cells = < 0x1 >;           /* in zephyr/dts/riscv/espressif/esp32c6/esp32c6_common.dtsi:299 */
			#size-cells = < 0x0 >;              /* in zephyr/dts/riscv/espressif/esp32c6/esp32c6_common.dtsi:300 */
			reg = < 0x6000c000 0x1000 >;        /* in zephyr/dts/riscv/espressif/esp32c6/esp32c6_common.dtsi:301 */
			interrupts = < 0x29 0x0 0x0 >;      /* in zephyr/dts/riscv/espressif/esp32c6/esp32c6_common.dtsi:302 */
			interrupt-parent = < &intc >;       /* in zephyr/dts/riscv/espressif/esp32c6/esp32c6_common.dtsi:303 */
			clocks = < &clock 0x5 >;            /* in zephyr/dts/riscv/espressif/esp32c6/esp32c6_common.dtsi:304 */
			unit = < 0x0 >;                     /* in zephyr/dts/riscv/espressif/esp32c6/esp32c6_common.dtsi:305 */
			status = "disabled";                /* in zephyr/dts/riscv/espressif/esp32c6/esp32c6_common.dtsi:306 */
		};

		/* node '/soc/uart@60000000' defined in zephyr/dts/riscv/espressif/esp32c6/esp32c6_common.dtsi:309 */
		uart0: uart@60000000 {
			compatible = "espressif,esp32-uart"; /* in zephyr/dts/riscv/espressif/esp32c6/esp32c6_common.dtsi:310 */
			reg = < 0x60000000 0x1000 >;         /* in zephyr/dts/riscv/espressif/esp32c6/esp32c6_common.dtsi:311 */
			interrupts = < 0x2b 0x0 0x0 >;       /* in zephyr/dts/riscv/espressif/esp32c6/esp32c6_common.dtsi:313 */
			interrupt-parent = < &intc >;        /* in zephyr/dts/riscv/espressif/esp32c6/esp32c6_common.dtsi:314 */
			clocks = < &clock 0x1 >;             /* in zephyr/dts/riscv/espressif/esp32c6/esp32c6_common.dtsi:315 */
			status = "okay";                     /* in zephyr/boards/espressif/esp32c6_devkitc/esp32c6_devkitc_hpcore.dts:43 */
			current-speed = < 0x1c200 >;         /* in zephyr/boards/espressif/esp32c6_devkitc/esp32c6_devkitc_hpcore.dts:44 */
			pinctrl-0 = < &uart0_default >;      /* in zephyr/boards/espressif/esp32c6_devkitc/esp32c6_devkitc_hpcore.dts:45 */
			pinctrl-names = "default";           /* in zephyr/boards/espressif/esp32c6_devkitc/esp32c6_devkitc_hpcore.dts:46 */
		};

		/* node '/soc/uart@60001000' defined in zephyr/dts/riscv/espressif/esp32c6/esp32c6_common.dtsi:318 */
		uart1: uart@60001000 {
			compatible = "espressif,esp32-uart"; /* in zephyr/dts/riscv/espressif/esp32c6/esp32c6_common.dtsi:319 */
			reg = < 0x60001000 0x1000 >;         /* in zephyr/dts/riscv/espressif/esp32c6/esp32c6_common.dtsi:320 */
			status = "disabled";                 /* in zephyr/dts/riscv/espressif/esp32c6/esp32c6_common.dtsi:321 */
			interrupts = < 0x2c 0x0 0x0 >;       /* in zephyr/dts/riscv/espressif/esp32c6/esp32c6_common.dtsi:322 */
			interrupt-parent = < &intc >;        /* in zephyr/dts/riscv/espressif/esp32c6/esp32c6_common.dtsi:323 */
			clocks = < &clock 0x2 >;             /* in zephyr/dts/riscv/espressif/esp32c6/esp32c6_common.dtsi:324 */
			current-speed = < 0x1c200 >;         /* in zephyr/dts/riscv/espressif/esp32c6/esp32c6_common.dtsi:325 */
		};

		/* node '/soc/uart@600b1400' defined in zephyr/dts/riscv/espressif/esp32c6/esp32c6_common.dtsi:328 */
		lp_uart: uart@600b1400 {
			compatible = "espressif,esp32-lpuart"; /* in zephyr/dts/riscv/espressif/esp32c6/esp32c6_common.dtsi:329 */
			reg = < 0x600b1400 0x1000 >;           /* in zephyr/dts/riscv/espressif/esp32c6/esp32c6_common.dtsi:330 */
			status = "disabled";                   /* in zephyr/dts/riscv/espressif/esp32c6/esp32c6_common.dtsi:331 */
			current-speed = < 0x1c200 >;           /* in zephyr/dts/riscv/espressif/esp32c6/esp32c6_common.dtsi:332 */
		};

		/* node '/soc/uart@6000f000' defined in zephyr/dts/riscv/espressif/esp32c6/esp32c6_common.dtsi:335 */
		usb_serial: uart@6000f000 {
			compatible = "espressif,esp32-usb-serial"; /* in zephyr/dts/riscv/espressif/esp32c6/esp32c6_common.dtsi:336 */
			reg = < 0x6000f000 0x1000 >;               /* in zephyr/dts/riscv/espressif/esp32c6/esp32c6_common.dtsi:337 */
			status = "disabled";                       /* in zephyr/dts/riscv/espressif/esp32c6/esp32c6_common.dtsi:338 */
			interrupts = < 0x30 0x0 0x0 >;             /* in zephyr/dts/riscv/espressif/esp32c6/esp32c6_common.dtsi:339 */
			interrupt-parent = < &intc >;              /* in zephyr/dts/riscv/espressif/esp32c6/esp32c6_common.dtsi:340 */
			clocks = < &clock 0x3 >;                   /* in zephyr/dts/riscv/espressif/esp32c6/esp32c6_common.dtsi:341 */
		};

		/* node '/soc/ledc@60007000' defined in zephyr/dts/riscv/espressif/esp32c6/esp32c6_common.dtsi:344 */
		ledc0: ledc@60007000 {
			compatible = "espressif,esp32-ledc"; /* in zephyr/dts/riscv/espressif/esp32c6/esp32c6_common.dtsi:345 */
			pwm-controller;                      /* in zephyr/dts/riscv/espressif/esp32c6/esp32c6_common.dtsi:346 */
			#pwm-cells = < 0x3 >;                /* in zephyr/dts/riscv/espressif/esp32c6/esp32c6_common.dtsi:347 */
			reg = < 0x60007000 0x1000 >;         /* in zephyr/dts/riscv/espressif/esp32c6/esp32c6_common.dtsi:348 */
			clocks = < &clock 0x0 >;             /* in zephyr/dts/riscv/espressif/esp32c6/esp32c6_common.dtsi:349 */
			status = "disabled";                 /* in zephyr/dts/riscv/espressif/esp32c6/esp32c6_common.dtsi:350 */
		};

		/* node '/soc/mcpwm@60014000' defined in zephyr/dts/riscv/espressif/esp32c6/esp32c6_common.dtsi:353 */
		mcpwm0: mcpwm@60014000 {
			compatible = "espressif,esp32-mcpwm"; /* in zephyr/dts/riscv/espressif/esp32c6/esp32c6_common.dtsi:354 */
			reg = < 0x60014000 0x1000 >;          /* in zephyr/dts/riscv/espressif/esp32c6/esp32c6_common.dtsi:355 */
			interrupts = < 0x3d 0x0 0x0 >;        /* in zephyr/dts/riscv/espressif/esp32c6/esp32c6_common.dtsi:356 */
			interrupt-parent = < &intc >;         /* in zephyr/dts/riscv/espressif/esp32c6/esp32c6_common.dtsi:357 */
			clocks = < &clock 0x18 >;             /* in zephyr/dts/riscv/espressif/esp32c6/esp32c6_common.dtsi:358 */
			#pwm-cells = < 0x3 >;                 /* in zephyr/dts/riscv/espressif/esp32c6/esp32c6_common.dtsi:359 */
			status = "disabled";                  /* in zephyr/dts/riscv/espressif/esp32c6/esp32c6_common.dtsi:360 */
		};

		/* node '/soc/pcnt@60012000' defined in zephyr/dts/riscv/espressif/esp32c6/esp32c6_common.dtsi:363 */
		pcnt: pcnt@60012000 {
			compatible = "espressif,esp32-pcnt"; /* in zephyr/dts/riscv/espressif/esp32c6/esp32c6_common.dtsi:364 */
			reg = < 0x60012000 0x1000 >;         /* in zephyr/dts/riscv/espressif/esp32c6/esp32c6_common.dtsi:365 */
			interrupts = < 0x3e 0x0 0x0 >;       /* in zephyr/dts/riscv/espressif/esp32c6/esp32c6_common.dtsi:366 */
			interrupt-parent = < &intc >;        /* in zephyr/dts/riscv/espressif/esp32c6/esp32c6_common.dtsi:367 */
			clocks = < &clock 0xa >;             /* in zephyr/dts/riscv/espressif/esp32c6/esp32c6_common.dtsi:368 */
			status = "disabled";                 /* in zephyr/dts/riscv/espressif/esp32c6/esp32c6_common.dtsi:369 */
		};
	};

	/* node '/gpio_keys' defined in zephyr/boards/espressif/esp32c6_devkitc/esp32c6_devkitc_hpcore.dts:32 */
	gpio_keys {
		compatible = "gpio-keys"; /* in zephyr/boards/espressif/esp32c6_devkitc/esp32c6_devkitc_hpcore.dts:33 */

		/* node '/gpio_keys/button_1' defined in zephyr/boards/espressif/esp32c6_devkitc/esp32c6_devkitc_hpcore.dts:34 */
		user_button1: button_1 {
			label = "User SW1";          /* in zephyr/boards/espressif/esp32c6_devkitc/esp32c6_devkitc_hpcore.dts:35 */
			gpios = < &gpio0 0x9 0x11 >; /* in zephyr/boards/espressif/esp32c6_devkitc/esp32c6_devkitc_hpcore.dts:36 */
			zephyr,code = < 0xb >;       /* in zephyr/boards/espressif/esp32c6_devkitc/esp32c6_devkitc_hpcore.dts:37 */
		};
	};
};
